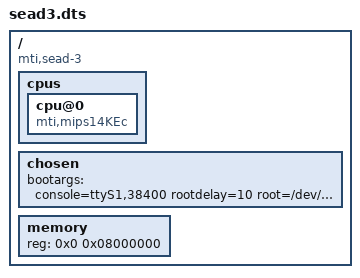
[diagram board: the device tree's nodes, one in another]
/dts-v1/;

/memreserve/ 0x00000000 0x00001000;	// reserved
/memreserve/ 0x00001000 0x000ef000;	// ROM data
/memreserve/ 0x000f0000 0x004cc000;	// reserved

/ {
	#address-cells = <1>;
	#size-cells = <1>;
	compatible = "mti,sead-3";

	cpus {
		cpu@0 {
			compatible = "mti,mips14KEc", "mti,mips14Kc";
		};
	};

	chosen {
		bootargs = "console=ttyS1,38400 rootdelay=10 root=/dev/sda3";
	};

	memory {
		device_type = "memory";
		reg = <0x0 0x08000000>;
	};
};
